VERSION ""

NS_ :

BS_:

BU_: DCU
VAL_TABLE_ OpCodeInfo 3 "MaxOpCodeIndex" 2 "SnrsFaultCodes" 1 "HWFaultCodes" 0 "InverterState" ;
VAL_TABLE_ OpCodeSignal 11 "MaxOpCodeIndex" 10 "DQAxesVoltages" 9 "PowerMeterInfo" 8 "PhaseVoltages" 7 "DQAxesCurrents" 6 "SpeedRefFdbck" 5 "TorqueRefFdbck" 4 "SpeedAndPosition" 3 "MeasuredVoltages" 2 "MeasuredCurrents" 1 "ExternalTemper" 0 "InternalTemper" ;

BO_ 3221225472 VECTOR__INDEPENDENT_SIG_MSG: 0 Vector__XXX
 SG_ Torque_Limit_Command : 0|16@1+ (0.1,-3276.8) [-3276.8|3276.7] "Nm" Vector__XXX
 SG_ Motor_Temperature : 0|8@1+ (1,-50) [-50|200] "degC" Vector__XXX
 SG_ Aux3_Temperature : 0|8@1+ (1,-50) [-50|200] "degC" Vector__XXX
 SG_ Speed_Reference : 0|16@1+ (1,-32768) [-32760|32760] "rpm" Vector__XXX
 SG_ Inverter_Fault_Critical : 0|1@1+ (1,0) [0|1] "" Vector__XXX
 SG_ Inverter_Fault : 0|1@1+ (1,0) [0|1] "" Vector__XXX
 SG_ Inverter_Warning : 0|1@1+ (1,0) [0|1] "" Vector__XXX
 SG_ Motor_SM : 0|16@1+ (1,0) [0|65535] "" Vector__XXX

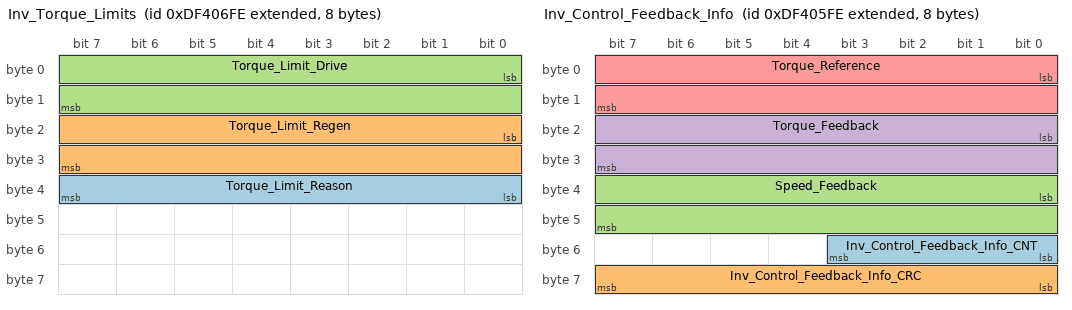
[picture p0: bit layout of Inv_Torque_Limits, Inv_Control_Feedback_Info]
BO_ 2381580030 Inv_Torque_Limits: 8 Vector__XXX
 SG_ Torque_Limit_Reason : 32|8@1+ (1,0) [0|255] "" Vector__XXX
 SG_ Torque_Limit_Regen : 16|16@1+ (0.1,0) [0|6553.5] "" Vector__XXX
 SG_ Torque_Limit_Drive : 0|16@1+ (0.1,0) [0|6553.5] "" Vector__XXX

BO_ 2381579774 Inv_Control_Feedback_Info: 8 Vector__XXX
 SG_ Inv_Control_Feedback_Info_CNT : 48|4@1+ (1,0) [0|15] "" Vector__XXX
 SG_ Inv_Control_Feedback_Info_CRC : 56|8@1+ (1,0) [0|255] "" Vector__XXX
 SG_ Speed_Feedback : 32|16@1+ (1,-32768) [-32760|32760] "rpm" Vector__XXX
 SG_ Torque_Feedback : 16|16@1+ (0.1,-3276.8) [-3148|3148] "Nm" Vector__XXX
 SG_ Torque_Reference : 0|16@1+ (0.1,-3276.8) [-3148|3148] "Nm" Vector__XXX

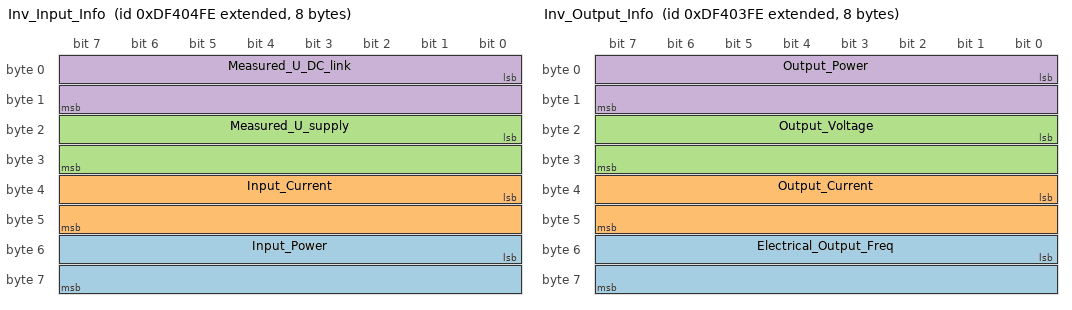
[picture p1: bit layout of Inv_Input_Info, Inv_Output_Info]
BO_ 2381579518 Inv_Input_Info: 8 Vector__XXX
 SG_ Input_Power : 48|16@1+ (0.01,-327.68) [-327.6|327.6] "kW" Vector__XXX
 SG_ Input_Current : 32|16@1+ (0.1,-3276.8) [-3148|3148] "Amps" Vector__XXX
 SG_ Measured_U_supply : 16|16@1+ (0.01,0) [0|60] "V" Vector__XXX
 SG_ Measured_U_DC_link : 0|16@1+ (0.1,0) [0|640] "V" Vector__XXX

BO_ 2381579262 Inv_Output_Info: 8 Vector__XXX
 SG_ Electrical_Output_Freq : 48|16@1+ (0.1,-3276.8) [-3148|3148] "Hz" Vector__XXX
 SG_ Output_Current : 32|16@1+ (0.1,-3276.8) [-3148|3148] "Amps" Vector__XXX
 SG_ Output_Voltage : 16|16@1+ (0.1,-3276.8) [-3148|3148] "V" Vector__XXX
 SG_ Output_Power : 0|16@1+ (0.01,-327.68) [-327.6|327.6] "kW" Vector__XXX

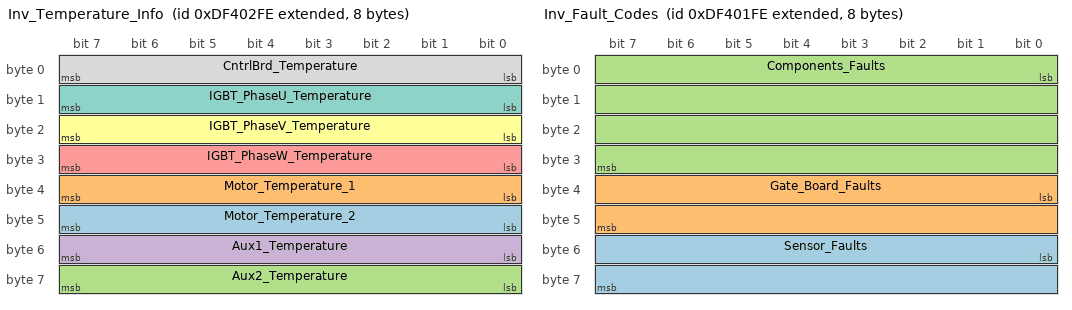
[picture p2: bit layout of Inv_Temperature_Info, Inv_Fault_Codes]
BO_ 2381579006 Inv_Temperature_Info: 8 Vector__XXX
 SG_ Motor_Temperature_2 : 40|8@1+ (1,-50) [-50|200] "degC" Vector__XXX
 SG_ Motor_Temperature_1 : 32|8@1+ (1,-50) [-50|200] "degC" Vector__XXX
 SG_ Aux2_Temperature : 56|8@1+ (1,-50) [-50|200] "degC" Vector__XXX
 SG_ Aux1_Temperature : 48|8@1+ (1,-50) [-50|200] "degC" Vector__XXX
 SG_ IGBT_PhaseW_Temperature : 24|8@1+ (1,-50) [-50|200] "degC" Vector__XXX
 SG_ IGBT_PhaseV_Temperature : 16|8@1+ (1,-50) [-50|200] "degC" Vector__XXX
 SG_ IGBT_PhaseU_Temperature : 8|8@1+ (1,-50) [-50|200] "degC" Vector__XXX
 SG_ CntrlBrd_Temperature : 0|8@1+ (1,-50) [-50|200] "degC" Vector__XXX

BO_ 2381578750 Inv_Fault_Codes: 8 Vector__XXX
 SG_ Sensor_Faults : 48|16@1+ (1,0) [0|65535] "" Vector__XXX
 SG_ Gate_Board_Faults : 32|16@1+ (1,0) [0|65535] "" Vector__XXX
 SG_ Components_Faults : 0|32@1+ (1,0) [0|4294967295] "" Vector__XXX

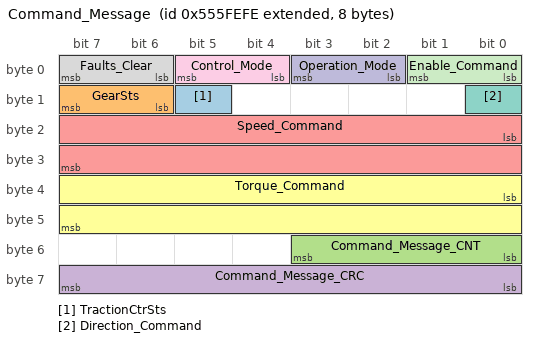
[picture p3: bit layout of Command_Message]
BO_ 2237005566 Command_Message: 8 Vector__XXX
 SG_ TractionCtrSts : 13|1@1+ (1,0) [0|1] "" Vector__XXX
 SG_ GearSts : 14|2@1+ (1,0) [0|3] "" Vector__XXX
 SG_ Command_Message_CNT : 48|4@1+ (1,0) [0|15] "" Vector__XXX
 SG_ Command_Message_CRC : 56|8@1+ (1,0) [0|255] "" Vector__XXX
 SG_ Speed_Command : 16|16@1+ (1,-32768) [-32768|32767] "rpm" Vector__XXX
 SG_ Torque_Command : 32|16@1+ (0.1,-3276.8) [-3276.8|3276.7] "Nm" Vector__XXX
 SG_ Direction_Command : 8|1@1+ (1,0) [0|1] "" Vector__XXX
 SG_ Faults_Clear : 6|2@1+ (1,0) [0|3] "" Vector__XXX
 SG_ Control_Mode : 4|2@1+ (1,0) [0|3] "" Vector__XXX
 SG_ Operation_Mode : 2|2@1+ (1,0) [0|3] "" Vector__XXX
 SG_ Enable_Command : 0|2@1+ (1,0) [0|3] "" Vector__XXX

BO_ 2247360766 Inv_State_Info: 8 Vector__XXX
 SG_ Inv_State_Info_CNT : 48|4@1+ (1,0) [0|15] "" Vector__XXX
 SG_ Inv_State_Info_CRC : 56|8@1+ (1,0) [0|255] "" Vector__XXX
 SG_ PWM_State : 5|2@1+ (1,0) [0|3] "" Vector__XXX
 SG_ INV_FS_005 : 20|1@1+ (1,0) [0|1] "" Vector__XXX
 SG_ INV_FS_004 : 19|1@1+ (1,0) [0|1] "" Vector__XXX
 SG_ INV_FS_003 : 18|1@1+ (1,0) [0|1] "" Vector__XXX
 SG_ INV_FS_002 : 17|1@1+ (1,0) [0|1] "" Vector__XXX
 SG_ INV_FS_001 : 16|1@1+ (1,0) [0|1] "" Vector__XXX
 SG_ Active_Discharge_State : 30|2@1+ (1,0) [0|3] "" Vector__XXX
 SG_ Res_Calibration_State : 28|2@1+ (1,0) [0|3] "" Vector__XXX
 SG_ BEMF_State : 26|2@1+ (1,0) [0|3] "" Vector__XXX
 SG_ Enable_State : 24|2@1+ (1,0) [0|3] "" Vector__XXX
 SG_ ESTOP_Signal_State : 4|1@1+ (1,0) [0|1] "" Vector__XXX
 SG_ KL15_Signal_State : 3|1@1+ (1,0) [0|1] "" Vector__XXX
 SG_ Direction_State : 14|1@1+ (1,0) [0|1] "" Vector__XXX
 SG_ MotorControlSig : 8|2@1+ (1,0) [0|3] "" Vector__XXX
 SG_ Control_Mode : 12|2@1+ (1,0) [0|3] "" Vector__XXX
 SG_ Operation_Mode : 10|2@1+ (1,0) [0|3] "" Vector__XXX
 SG_ Precharge_State : 1|1@1+ (1,0) [0|1] "" Vector__XXX
 SG_ Ready_State : 2|1@1+ (1,0) [0|1] "" Vector__XXX
 SG_ Init_State : 0|1@1+ (1,0) [0|1] "" Vector__XXX
 SG_ Main_SM : 32|16@1+ (1,0) [0|65535] "" Vector__XXX

CM_ BO_ 3221225472 "This is a message for not used signals, created by Vector CANdb++ DBC OLE DB Provider.";
CM_ SG_ 3221225472 Torque_Limit_Command "Torque Limit, set to 0 to keep default";
CM_ SG_ 3221225472 Motor_Temperature "Temperature of the motor";
CM_ SG_ 3221225472 Aux3_Temperature "Temperature of the auxiliary input 3";
CM_ SG_ 3221225472 Speed_Reference "Internal reference value of the speed";
CM_ SG_ 3221225472 Inverter_Fault_Critical "Inverter critical fault status.";
CM_ SG_ 3221225472 Inverter_Fault "Inverter fault status.";
CM_ SG_ 3221225472 Inverter_Warning "Inverter warning status.";
CM_ SG_ 3221225472 Motor_SM "Current state of the inverter low level state machine";
CM_ BO_ 2381580030 "The available torque and the reason for the limitation";
CM_ SG_ 2381580030 Torque_Limit_Reason "Reason of torque limitation";
CM_ SG_ 2381580030 Torque_Limit_Regen "Maximum allowable torque in regeneration mode";
CM_ SG_ 2381580030 Torque_Limit_Drive "Maximum allowable torque in drive mode";
CM_ BO_ 2381579774 "Speed and torque reference and feedback values. When inverter in torque control mode Speed_Reference equal zero.";
CM_ SG_ 2381579774 Inv_Control_Feedback_Info_CNT "Inv_Control_Feedback_Info E2E message counter";
CM_ SG_ 2381579774 Inv_Control_Feedback_Info_CRC "Inv_Control_Feedback_Info E2E CRC";
CM_ SG_ 2381579774 Speed_Feedback "Estimated value of the speed";
CM_ SG_ 2381579774 Torque_Feedback "Estimated value of the torque";
CM_ SG_ 2381579774 Torque_Reference "Internal reference value of the torque";
CM_ BO_ 2381579518 "Measured and calculated values at the inverter input";
CM_ SG_ 2381579518 Input_Power "Estimated inverter input power";
CM_ SG_ 2381579518 Input_Current "Estimated inverter input DC current";
CM_ SG_ 2381579518 Measured_U_supply "Measured supply voltage";
CM_ SG_ 2381579518 Measured_U_DC_link "Measured DC-link voltage";
CM_ BO_ 2381579262 "Measured and calculated values at the inverter output";
CM_ SG_ 2381579262 Electrical_Output_Freq "Calculated value of the output electrical frequency";
CM_ SG_ 2381579262 Output_Current "Generalized output current";
CM_ SG_ 2381579262 Output_Voltage "Calculated inverter output voltage";
CM_ SG_ 2381579262 Output_Power "Estimated inverter output power";
CM_ BO_ 2381579006 "Temperature values of Inverter, motor and auxiliary sensors";
CM_ SG_ 2381579006 Motor_Temperature_2 "Sensor 2 motor temperature";
CM_ SG_ 2381579006 Motor_Temperature_1 "Sensor 1 motor temperature";
CM_ SG_ 2381579006 Aux2_Temperature "Temperature of the auxiliary input 2";
CM_ SG_ 2381579006 Aux1_Temperature "Temperature of the auxiliary input 1";
CM_ SG_ 2381579006 IGBT_PhaseW_Temperature "Temperature of the phase W IGBT module";
CM_ SG_ 2381579006 IGBT_PhaseV_Temperature "Temperature of the phase V IGBT module";
CM_ SG_ 2381579006 IGBT_PhaseU_Temperature "Temperature of the phase U IGBT module";
CM_ SG_ 2381579006 CntrlBrd_Temperature "Temperature of the inverter control board";
CM_ BO_ 2381578750 "Inverter fault codes";
CM_ SG_ 2381578750 Sensor_Faults "Each bit represents sensor fault. Please refer to documentation for details.";
CM_ SG_ 2381578750 Gate_Board_Faults "Each bit represents a gate board fault. Please refer to documentation for details.";
CM_ SG_ 2381578750 Components_Faults "Each bit represents in inverter component fault. Please refer to documentation for details.";
CM_ BO_ 2237005566 "Inverter command message";
CM_ SG_ 2237005566 Command_Message_CNT "Command_Message E2E message counter";
CM_ SG_ 2237005566 Command_Message_CRC "Command_Message E2E CRC";
CM_ SG_ 2237005566 Speed_Command "Speed command used when in speed mode";
CM_ SG_ 2237005566 Torque_Command "Torque command used when in torque mode";
CM_ SG_ 2237005566 Direction_Command "Motor rotation direction as viewed from the shaft end of the motor";
CM_ SG_ 2237005566 Faults_Clear "Faults clear command";
CM_ SG_ 2237005566 Control_Mode "Motor control mode";
CM_ SG_ 2237005566 Operation_Mode "Inverter operation mode";
CM_ SG_ 2237005566 Enable_Command "Turn on command";
CM_ BO_ 2247360766 "Information about Inverter states";
CM_ SG_ 2247360766 Inv_State_Info_CNT "Inv_State_Info E2E message counter";
CM_ SG_ 2247360766 Inv_State_Info_CRC "Inv_State_Info E2E CRC";
CM_ SG_ 2247360766 PWM_State "The state of the PWM outputs of the inverter
0 - OC state
1 - PWM ON
2 - ASC
3 - Not valid";
CM_ SG_ 2247360766 INV_FS_005 "1 - Inverter is in emergency critical fault state";
CM_ SG_ 2247360766 INV_FS_004 "1 - Inverter is in critical fault state";
CM_ SG_ 2247360766 INV_FS_003 "1- Inverter is in fault state";
CM_ SG_ 2247360766 INV_FS_002 "1 - Inverter is in limp mode";
CM_ SG_ 2247360766 INV_FS_001 "1 - Inverter is in warning state";
CM_ SG_ 2247360766 Active_Discharge_State "State of the active discharge";
CM_ SG_ 2247360766 Res_Calibration_State "Resolver calibration state feedback";
CM_ SG_ 2247360766 BEMF_State "Motor BEMF state, 0x0 - 0...33%, 0x1 - 33.3...66.6%, 0x2 - 66.6...100%, 0x3 - >100%";
CM_ SG_ 2247360766 Enable_State "Inverter enable state signal.";
CM_ SG_ 2247360766 ESTOP_Signal_State "State of the ESTOP signal";
CM_ SG_ 2247360766 KL15_Signal_State "State of the KL15 signal";
CM_ SG_ 2247360766 Direction_State "Motor rotation direction as viewed from the shaft end of the motor";
CM_ SG_ 2247360766 MotorControlSig "Internal motor start/stop command";
CM_ SG_ 2247360766 Control_Mode "Motor control mode";
CM_ SG_ 2247360766 Operation_Mode "Inverter operation mode";
CM_ SG_ 2247360766 Precharge_State "Precharge process state";
CM_ SG_ 2247360766 Ready_State "Inverter ready state";
CM_ SG_ 2247360766 Init_State "Motor control initialization process state";
CM_ SG_ 2247360766 Main_SM "Current state of the inverter high level state machine";
BA_DEF_ BO_  "PpCcGenMsgType" STRING ;
BA_DEF_ SG_  "SigType" ENUM  "Default","Range","RangeSigned","ASCII","Discrete","Control","ReferencePGN","DTC","StringDelimiter","StringLength","StringLengthControl","MessageCounter","MessageChecksum";
BA_DEF_ SG_  "GenSigEVName" STRING ;
BA_DEF_ SG_  "GenSigILSupport" ENUM  "No","Yes";
BA_DEF_ SG_  "GenSigSendType" ENUM  "Cyclic","OnWrite","OnWriteWithRepetition","OnChange","OnChangeWithRepetition","IfActive","IfActiveWithRepetition","NoSigSendType";
BA_DEF_ SG_  "GenSigStartValue" INT 0 2147483647;
BA_DEF_ BO_  "GenMsgILSupport" ENUM  "No","Yes";
BA_DEF_ BU_  "NmStationAddress" INT 0 255;
BA_DEF_ BO_  "GenMsgSendType" ENUM  "cyclic","NotUsed","IfActive","NotUsed","NotUsed","NotUsed","NotUsed","NotUsed","noMsgSendType";
BA_DEF_ BO_  "GenMsgRequestable" INT 0 1;
BA_DEF_ BO_  "GenMsgCycleTime" INT 0 3600000;
BA_DEF_  "DBName" STRING ;
BA_DEF_  "BusType" STRING ;
BA_DEF_  "ProtocolType" STRING ;
BA_DEF_ BO_  "VFrameFormat" ENUM  "StandardCAN","ExtendedCAN","reserved","J1939PG";
BA_DEF_DEF_  "PpCcGenMsgType" "PpCcUndefined";
BA_DEF_DEF_  "SigType" "Default";
BA_DEF_DEF_  "GenSigEVName" "Env@Nodename_@Signame";
BA_DEF_DEF_  "GenSigILSupport" "Yes";
BA_DEF_DEF_  "GenSigSendType" "NoSigSendType";
BA_DEF_DEF_  "GenSigStartValue" 0;
BA_DEF_DEF_  "GenMsgILSupport" "Yes";
BA_DEF_DEF_  "NmStationAddress" 254;
BA_DEF_DEF_  "GenMsgSendType" "noMsgSendType";
BA_DEF_DEF_  "GenMsgRequestable" 1;
BA_DEF_DEF_  "GenMsgCycleTime" 0;
BA_DEF_DEF_  "DBName" "";
BA_DEF_DEF_  "BusType" "CAN";
BA_DEF_DEF_  "ProtocolType" "J1939";
BA_DEF_DEF_  "VFrameFormat" "J1939PG";
BA_ "DBName" "Traction_Inverter";
BA_ "NmStationAddress" BU_ DCU 100;
BA_ "PpCcGenMsgType" BO_ 2381580030 "PpCcOutput";
BA_ "GenMsgCycleTime" BO_ 2381580030 10;
BA_ "PpCcGenMsgType" BO_ 2381579774 "PpCcOutput";
BA_ "GenMsgCycleTime" BO_ 2381579774 10;
BA_ "PpCcGenMsgType" BO_ 2381579518 "PpCcOutput";
BA_ "GenMsgCycleTime" BO_ 2381579518 100;
BA_ "PpCcGenMsgType" BO_ 2381579262 "PpCcOutput";
BA_ "GenMsgCycleTime" BO_ 2381579262 100;
BA_ "PpCcGenMsgType" BO_ 2381579006 "PpCcOutput";
BA_ "GenMsgCycleTime" BO_ 2381579006 1000;
BA_ "PpCcGenMsgType" BO_ 2381578750 "PpCcOutput";
BA_ "GenMsgCycleTime" BO_ 2381578750 1000;
BA_ "PpCcGenMsgType" BO_ 2237005566 "PpCcInput";
BA_ "GenMsgCycleTime" BO_ 2237005566 10;
BA_ "PpCcGenMsgType" BO_ 2247360766 "PpCcOutput";
BA_ "GenMsgCycleTime" BO_ 2247360766 10;
BA_ "GenSigStartValue" SG_ 3221225472 Torque_Limit_Command 32768;
BA_ "SigType" SG_ 3221225472 Motor_Temperature 1;
BA_ "GenSigStartValue" SG_ 3221225472 Motor_Temperature 50;
BA_ "SigType" SG_ 3221225472 Aux3_Temperature 1;
BA_ "GenSigStartValue" SG_ 3221225472 Aux3_Temperature 50;
BA_ "GenSigStartValue" SG_ 3221225472 Speed_Reference 32768;
BA_ "SigType" SG_ 2381579774 Inv_Control_Feedback_Info_CNT 11;
BA_ "SigType" SG_ 2381579774 Inv_Control_Feedback_Info_CRC 12;
BA_ "GenSigStartValue" SG_ 2381579774 Speed_Feedback 32768;
BA_ "GenSigStartValue" SG_ 2381579774 Torque_Feedback 32768;
BA_ "GenSigStartValue" SG_ 2381579774 Torque_Reference 32768;
BA_ "GenSigStartValue" SG_ 2381579518 Input_Power 32768;
BA_ "GenSigStartValue" SG_ 2381579518 Input_Current 32768;
BA_ "SigType" SG_ 2381579518 Measured_U_supply 1;
BA_ "SigType" SG_ 2381579518 Measured_U_DC_link 1;
BA_ "GenSigStartValue" SG_ 2381579262 Electrical_Output_Freq 32768;
BA_ "SigType" SG_ 2381579262 Output_Current 1;
BA_ "GenSigStartValue" SG_ 2381579262 Output_Current 32768;
BA_ "GenSigStartValue" SG_ 2381579262 Output_Voltage 32768;
BA_ "SigType" SG_ 2381579262 Output_Voltage 1;
BA_ "GenSigStartValue" SG_ 2381579262 Output_Power 32768;
BA_ "SigType" SG_ 2381579006 Motor_Temperature_2 1;
BA_ "GenSigStartValue" SG_ 2381579006 Motor_Temperature_2 50;
BA_ "SigType" SG_ 2381579006 Motor_Temperature_1 1;
BA_ "GenSigStartValue" SG_ 2381579006 Motor_Temperature_1 50;
BA_ "SigType" SG_ 2381579006 Aux2_Temperature 1;
BA_ "GenSigStartValue" SG_ 2381579006 Aux2_Temperature 50;
BA_ "SigType" SG_ 2381579006 Aux1_Temperature 1;
BA_ "GenSigStartValue" SG_ 2381579006 Aux1_Temperature 50;
BA_ "SigType" SG_ 2381579006 IGBT_PhaseW_Temperature 1;
BA_ "GenSigStartValue" SG_ 2381579006 IGBT_PhaseW_Temperature 50;
BA_ "SigType" SG_ 2381579006 IGBT_PhaseV_Temperature 1;
BA_ "GenSigStartValue" SG_ 2381579006 IGBT_PhaseV_Temperature 50;
BA_ "SigType" SG_ 2381579006 IGBT_PhaseU_Temperature 1;
BA_ "GenSigStartValue" SG_ 2381579006 IGBT_PhaseU_Temperature 50;
BA_ "SigType" SG_ 2381579006 CntrlBrd_Temperature 1;
BA_ "GenSigStartValue" SG_ 2381579006 CntrlBrd_Temperature 50;
BA_ "SigType" SG_ 2237005566 Command_Message_CNT 11;
BA_ "SigType" SG_ 2237005566 Command_Message_CRC 12;
BA_ "GenSigStartValue" SG_ 2237005566 Speed_Command 32768;
BA_ "GenSigStartValue" SG_ 2237005566 Torque_Command 32768;
BA_ "SigType" SG_ 2247360766 Inv_State_Info_CNT 11;
BA_ "SigType" SG_ 2247360766 Inv_State_Info_CRC 12;
VAL_ 3221225472 Motor_SM 2048 "ActiveDischarge" 32768 "Fault" 16384 "Stop to Fault" 1024 "Resolver Calibration" 512 "Stop to Idle" 256 "Stop" 128 "Any Stop" 64 "Run" 32 "Start Run" 16 "Clear" 8 "Offset_Calibration" 4 "Idle Start" 2 "Idle" 0 "Init" ;
VAL_ 2381580030 Torque_Limit_Reason 9 "DC-link Voltage" 8 "Speed Rate Limit" 7 "Voltage Rate Limit" 6 "Motor Speed Limit" 5 "Motor Current Derating" 255 "Reason Illegal" 4 "Motor Power Derating" 3 "Inverter Current Derating" 2 "Default Inverter Power" 1 "Default Inverter Current" 0 "Default Motor Torque" ;
VAL_ 2237005566 TractionCtrSts 1 "Active" 0 "Inactive" ;
VAL_ 2237005566 GearSts 3 "Shifting In Progress" 2 "Second Gear" 1 "First Gear" 0 "Neutral" ;
VAL_ 2237005566 Direction_Command 1 "CCW" 0 "CW" ;
VAL_ 2237005566 Faults_Clear 3 "Clear Faults" 2 "TakeNoAction" 1 "TakeNoAction" 0 "TakeNoAction" ;
VAL_ 2237005566 Control_Mode 3 "Not Valid" 2 "Torque Mode" 1 "Speed Mode" 0 "Not Selected" ;
VAL_ 2237005566 Operation_Mode 3 "MotorControl" 2 "ActiveDischarge" 1 "Calibration" 0 "Not Selected" ;
VAL_ 2237005566 Enable_Command 3 "Turn ON" 2 "Not Valid" 1 "Not Valid" 0 "Turn OFF" ;
VAL_ 2247360766 PWM_State 3 "Not valid" 2 "PWM_ASC_SW" 1 "PWM_ON" 0 "PWM_OFF" ;
VAL_ 2247360766 Active_Discharge_State 3 "Active Discharge Success" 2 "Active Discharge Error" 1 "Active Discharge In Progress" 0 "Active Discharge Not Active" ;
VAL_ 2247360766 Res_Calibration_State 3 "Calibration Success" 2 "Calibration Error" 1 "Calibration Begin" 0 "Calibration Not Active" ;
VAL_ 2247360766 BEMF_State 3 "Above 100 percent" 2 "66_100 percent" 1 "33_66 percent" 0 "0_33 percent" ;
VAL_ 2247360766 Enable_State 3 "Not Valid" 2 "Inverter Enabled" 1 "Inverter Disabling In Progress" 0 "Inverter Disabled" ;
VAL_ 2247360766 ESTOP_Signal_State 1 "High State" 0 "Low State" ;
VAL_ 2247360766 KL15_Signal_State 1 "High State" 0 "Low State" ;
VAL_ 2247360766 Direction_State 1 "CCW" 0 "CW" ;
VAL_ 2247360766 MotorControlSig 3 "Not Valid" 2 "Motor Stop" 1 "Motor Start" 0 "Not Valid" ;
VAL_ 2247360766 Control_Mode 3 "Not Valid" 2 "Torque Mode" 1 "Speed Mode" 0 "Not Selected" ;
VAL_ 2247360766 Operation_Mode 3 "MotorControl" 2 "ActiveDischarge" 1 "Calibration" 0 "Not Selected" ;
VAL_ 2247360766 Precharge_State 1 "Charged" 0 "Discharged" ;
VAL_ 2247360766 Ready_State 1 "Ready" 0 "Not Ready" ;
VAL_ 2247360766 Init_State 1 "Initialized" 0 "Not Initialized" ;
VAL_ 2247360766 Main_SM 256 "Stop_To_Precharge" 32768 "Fault" 16384 "Stop_To_Fault" 128 "ActiveDischarge" 64 "Calibration" 32 "Stop_To_Idle" 16 "Run_Torque_Control" 8 "Run_Speed_Control" 4 "Start" 2 "Idle" 1 "Precharge" 0 "Initialization" ;
